AUTOSAR XML (schema 314)
package /ComponentType
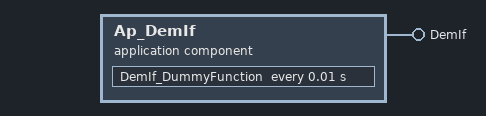
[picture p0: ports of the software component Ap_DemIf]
  application software component type Ap_DemIf
    provide port DemIf: provided-interface=DemIf
      provided-com-specs:
        operation=DemShutdown, queue-length=1
        operation=RestartDem, queue-length=1
        operation=SetEventStatus, queue-length=1
        operation=SetOperationCycleState, queue-length=1
  internal behavior Ap_DemIf_InternalBehavior: component=Ap_DemIf, port-api-option{enable-take-address=false, indirect-api=false, port=DemIf}
    operation invoked event OIT_DemIf_DemShutdown_DemIf_DemShutdown: start-on-event=DemIf_DemShutdown, operation=DemIf.DemShutdown
    timing event TMT_DemIf_DummyFunction: start-on-event=DemIf_DummyFunction, period=0.01
    operation invoked event OIT_DemIf_RestartDem_DemIf_RestartDem: start-on-event=DemIf_RestartDem, operation=DemIf.RestartDem
    operation invoked event OIT_DemIf_SetEventStatus_DemIf_SetEventStatus: start-on-event=DemIf_SetEventStatus, operation=DemIf.SetEventStatus
    operation invoked event OIT_DemIf_SetOperationCycleState_DemIf_SetOperationCycleState: start-on-event=DemIf_SetOperationCycleState, operation=DemIf.SetOperationCycleState
    5 x runnable:
      DemIf_DemShutdown
      DemIf_DummyFunction
      DemIf_RestartDem
      DemIf_SetEventStatus
      DemIf_SetOperationCycleState: can-be-invoked-concurrently=true
  swc implementation Ap_DemIf_Implementation: behavior=Ap_DemIf_InternalBehavior
    code-descriptors:
      code Code: type=SRC
